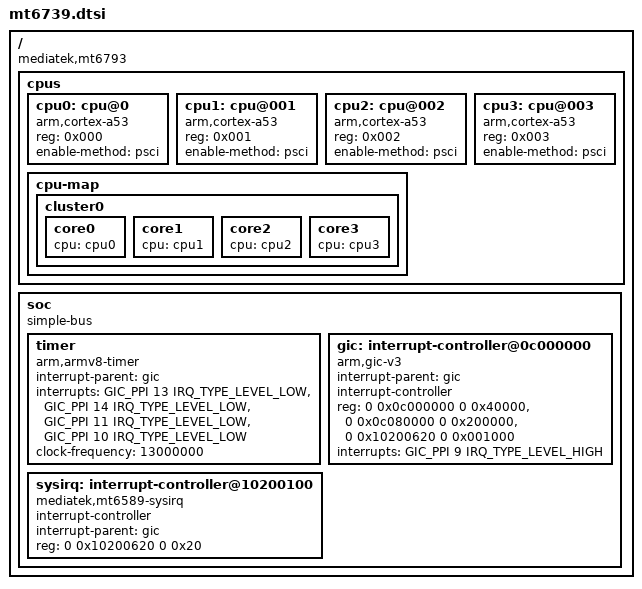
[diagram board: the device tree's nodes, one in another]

#include <dt-bindings/interrupt-controller/irq.h>
#include <dt-bindings/interrupt-controller/arm-gic.h>

/ {
    #address-cells = <1>;
    #size-cells = <1>;
    compatible = "mediatek,mt6793";
    cpus {
        #address-cells = <1>;
        #size-cells = <0>;
        cpu0: cpu@0 {
            device_type = "cpu";
            compatible = "arm,cortex-a53";
            reg = <0x000>;
            enable-method = "psci";
        };

        cpu1: cpu@001 {
            device_type = "cpu";
            compatible = "arm,cortex-a53";
            reg = <0x001>;
            enable-method = "psci";
        };

        cpu2: cpu@002 {
            device_type = "cpu";
            compatible = "arm,cortex-a53";
            reg = <0x002>;
            enable-method = "psci";
        };

        cpu3: cpu@003 {
            device_type = "cpu";
            compatible = "arm,cortex-a53";
            reg = <0x003>;
            enable-method = "psci";
        };

        cpu-map {
            cluster0 {
                core0 {
                    cpu = <&cpu0>;
                };
                core1 {
                    cpu = <&cpu1>;
                };
                core2 {
                    cpu = <&cpu2>;
                };
                core3 {
                    cpu = <&cpu3>;
                };

            };
        };
    };
        soc {
            #address-cells = <1>;
            #size-cells = <1>;
            compatible = "simple-bus";
            ranges;
                
        timer {
            compatible = "arm,armv8-timer";
            interrupt-parent = <&gic>;
            interrupts = <GIC_PPI 13 IRQ_TYPE_LEVEL_LOW>,
            <GIC_PPI 14 IRQ_TYPE_LEVEL_LOW>,
            <GIC_PPI 11 IRQ_TYPE_LEVEL_LOW>,
            <GIC_PPI 10 IRQ_TYPE_LEVEL_LOW>;
        clock-frequency = <13000000>;
                };
                
                gic: interrupt-controller@0c000000 {
          compatible = "arm,gic-v3";
          #interrupt-cells = <3>;
          interrupt-parent = <&gic>;
          interrupt-controller;
          reg = <0 0x0c000000 0 0x40000>, // distributor
              <0 0x0c080000 0 0x200000>, // redistributor
              <0 0x10200620 0 0x001000>; // INTPOL
          interrupts = <GIC_PPI 9 IRQ_TYPE_LEVEL_HIGH>;
            };
      
        sysirq: interrupt-controller@10200100 {
            compatible = "mediatek,mt6589-sysirq",
                         "mediatek,mt6577-sysirq";
            interrupt-controller;
            #interrupt-cells = <3>;
            interrupt-parent = <&gic>;
            reg = <0 0x10200620 0 0x20>;
        };
            };
};
